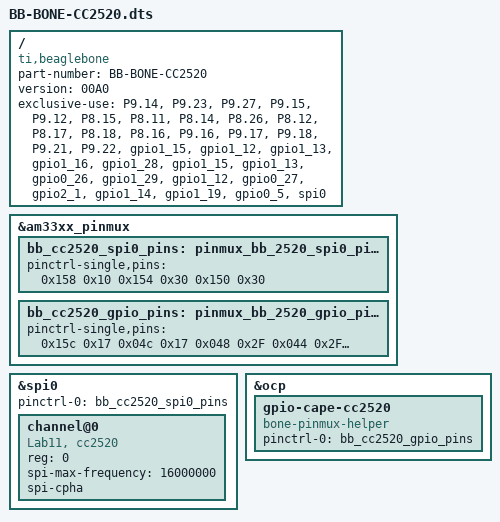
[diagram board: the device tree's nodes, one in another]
/*
 * Copyright (C) 2014 Neal Jackson, LAB11
 *
 * Cape for LAB11 cc2520 radio, utilizing gpio pins P8.15, P8.12, P8.11,
 * P9.15, P9.12, P8.17, P8.18, P8.16, and the spi0 device.
 *
 * This program is free software; you can redistribute it and/or modify
 * it under the terms of the GNU General Public License version 2 as
 * published by the Free Software Foundation.
 */

/dts-v1/;
/plugin/;
 
/ {
   	compatible = "ti,beaglebone", "ti,beaglebone-black";
 
        /* identification */
        part-number = "BB-BONE-CC2520";
        version = "00A0";
 
        /* state the resources this cape uses */
        exclusive-use =
                /* the pin header uses */

                /* GPIO */
                "P9.14",       /* SFD0: gpio1_18 */
                "P9.23",       /* FIFP0: gpio1_17 */
                "P9.27",       /* FIFO0: gpio3_19 */
                "P9.15",       /* RST0: gpio1_16 */
                "P9.12",       /* CCA0: gpio1_28 */

                "P8.15",       /* SFD1: gpio1_15 */
                "P8.11",       /* FIFP1: gpio1_13 */
                "P8.14",       /* FIFO1: gpio0_26 */
                "P8.26",       /* RST1: gpio1_29 */
                "P8.12",       /* CCA1: gpio1_12 */

                "P8.17",	   /* DEBUG0: gpio0_27 */
                "P8.18",	   /* DEBUG1: gpio2_1 */
                "P8.16",       /* DEBUG2: gpio1_14 */

                /* SPI */
                "P9.16",       /* CS1: gpio1_19 */
                "P9.17",       /* CS0: gpio0_5 */
                "P9.18",       /* MOSI: spi0_d1 */
                "P9.21",       /* MISO: spi0_d0 */
                "P9.22",       /* SCLK: spi0_sclk */

                /* the hardware ip uses */

                "gpio1_15",
                "gpio1_12",
                "gpio1_13",
                "gpio1_16",
                "gpio1_28",
                "gpio1_15",
                "gpio1_13",
                "gpio0_26",
                "gpio1_29",
                "gpio1_12",
                "gpio0_27",
                "gpio2_1",
                "gpio1_14",
                "gpio1_19",
                "gpio0_5",
                "spi0";
 
        fragment@0 {
                target = <&am33xx_pinmux>;
                __overlay__ {
                        bb_cc2520_spi0_pins: pinmux_bb_2520_spi0_pins {
                                pinctrl-single,pins = <
                                        //0x15c 0x10 /* i2c1_scl.spi0_cs0, OUTPUT_PULLUP | MODE0 */
                                        0x158 0x10 /* i2c1_sda.spi0_d1, OUTPUT_PULLUP | MODE0 */
                                        0x154 0x30 /* uart2_txd.spi0_d0, INPUT_PULLUP | MODE0 */
                                        0x150 0x30 /* uart2_rxd.spi0_sclk, INPUT_PULLUP | MODE0 */
                                >;
                        };
                        bb_cc2520_gpio_pins: pinmux_bb_2520_gpio_pins {
                        		pinctrl-single,pins = <
                                        /* SPI GPIO */
                                        0x15c 0x17 /* i2c1_scl.gpio0_5, OUTPUT_PULLUP | MODE7 */ //usually in mode 0 for cs0
                                        0x04c 0x17 /* ehrpwm1b.gpio1_19, OUTPUT_PULLUP | MODE7 */

                                        /* GPIO */
                                        0x048 0x2F /* ehrpwm1a.gpio1_18, INPUT | MODE7 */
                                        0x044 0x2F /* gpio1_17.gpio1_17, INPUT | MODE7 */
                                        0x1a4 0x2F /* gpio3_19.gpio3_19, INPUT | MODE7 */
                                        0x040 0x17 /* gpio1_16.gpio1_16, OUTPUT_PULLUP | MODE7 */
                                        0x078 0x2F /* gpio1_28.gpio1_28, INPUT | MODE7 */

                                        0x03c 0x2F /* gpio1_15.gpio1_15, INPUT | MODE7 */
                                        0x034 0x2F /* gpio1_13.gpio1_13, INPUT | MODE7 */
                                        0x028 0x2F /* gpio0_26.gpio0_26, INPUT | MODE7 */
                                        0x07c 0x17 /* gpio1_29.gpio1_29, OUTPUT_PULLUP | MODE7 */
                                        0x030 0x2F /* gpio1_12.gpio1_12, INPUT | MODE7 */

                                        0x02c 0x17 /* gpio0_27.gpio0_27, OUTPUT_PULLUP | MODE7 */
                                        0x08c 0x17 /* gpio2_1.gpio2_1, OUTPUT_PULLUP | MODE7 */
                                        0x38 0x17 /* gpio1_14.gpio1_14, OUTPUT_PULLUP | MODE7 */
                                >;
                        };
                };
        };
 
		fragment@1 {
                target = <&spi0>;	/* spi0 is numbered correctly */
                __overlay__ {
                		#address-cells = <1>;
                		#size-cells = <0>;

                        status = "okay";
                        pinctrl-names = "default";
                        pinctrl-0 = <&bb_cc2520_spi0_pins>;

                        channel@0 {
                        	#address-cells = <1>;
                        	#size-cells = <0>;

                        	compatible = "Lab11, cc2520";

                        	reg = <0>;
                        	spi-max-frequency = <16000000>;
                        	spi-cpha;
                        };
                };
        };

        fragment@2 {
        		target = <&ocp>;
        		__overlay__ {
        				
        				gpio-cape-cc2520 {
        					compatible = "bone-pinmux-helper";
                            pinctrl-names = "default";
        					pinctrl-0 = <&bb_cc2520_gpio_pins>;
                            status = "okay";
        				};
        		};
        };
};
